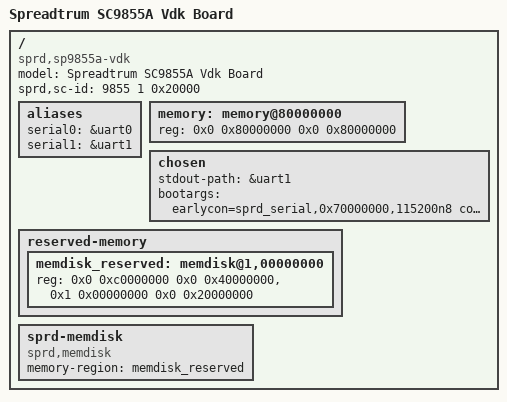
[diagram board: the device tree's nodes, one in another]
/*
 * Spreadtrum sharkl3 Vdk board DTS file
 *
 * Copyright (C) 2017, Spreadtrum Communications Inc.
 *
 * This file is licensed under a dual GPLv2 or X11 license.
 */
/dts-v1/;

#include "sc9855a.dtsi"
#include "sp9855a-common.dtsi"

/ {
	model = "Spreadtrum SC9855A Vdk Board";

	compatible = "sprd,sp9855a-vdk", "sprd,sc9855a";

	sprd,sc-id = <9855 1 0x20000>;

	aliases {
		serial0 = &uart0;
		serial1 = &uart1;
	};

	memory: memory@80000000 {
		device_type = "memory";
		reg = <0x0 0x80000000 0x0 0x80000000>;
	};

	chosen {
		stdout-path = &uart1;
		bootargs = "earlycon=sprd_serial,0x70000000,115200n8 console=ttyS1,115200n8 loglevel=8 init=/init root=/dev/ram0 rw androidboot.hardware=sharkl3 androidboot.selinux=permissive";
	};

	reserved-memory {
		#address-cells = <2>;
		#size-cells = <2>;
		ranges;

		memdisk_reserved: memdisk@1,00000000{
			reg = <0x0 0xc0000000 0x0 0x40000000>,	/* system */
				<0x1 0x00000000 0x0 0x20000000>; /* userdata */
		};
	};

	sprd-memdisk {
		compatible = "sprd,memdisk";
		memory-region = <&memdisk_reserved>;
	};
};

